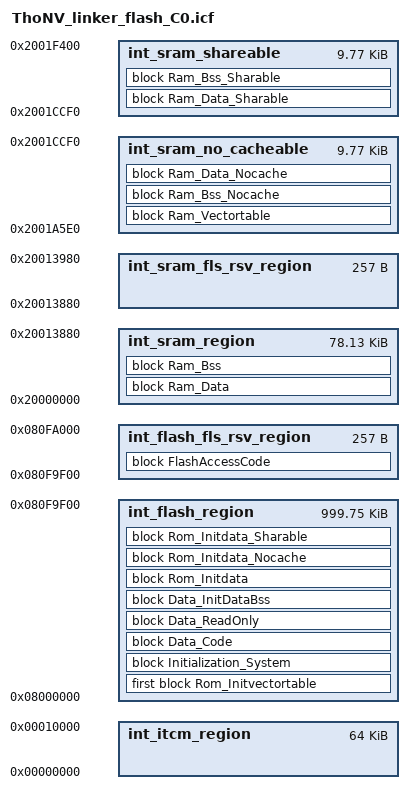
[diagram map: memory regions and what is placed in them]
define symbol region_ITCM_start                 = 0x00000000;
define symbol region_ITCM_end                   = 64K;    /* 64K */

define symbol region_DTCM_start                 = 0x10000000;
define symbol region_DTCM_end                   = 128K;    /* 128K */

define symbol region_FLASH_C0_start             = 0x08000000;
define symbol region_FLASH_C0_end               = 0x080F9F00; 

define symbol region_FLS_RSV_FLASH_C0_start     = 0x080F9F00;
define symbol region_FLS_RSV_FLASH_C0_end       = 0x080FA000; 

define symbol region_SRAM_C0_start              = 0x20000000;
define symbol region_SRAM_C0_end                = 0x20013880; 

define symbol region_FLS_RSV_RAM_C0_start       = 0x20013880;
define symbol region_FLS_RSV_RAM_C0_end         = 0x20013980; 

define symbol region_SRAM_STACK_C0_start       = 0x20013980;
define symbol region_SRAM_STACK_C0_end         = 0x2001A5E0; 

define symbol region_SRAM_NO_CACHEABLE_C0_start = 0x2001A5E0;
define symbol region_SRAM_NO_CACHEABLE_C0_end   = 0x2001CCF0;

define symbol region_SRAM_SHAREABLE_start       = 0x2001CCF0;
define symbol region_SRAM_SHAREABLE_end         = 0x2001F400; 

define symbol region_SRAM_END_C0                = 0x2001F400;

define exported symbol Stack_end_c0      = region_SRAM_STACK_C0_start;
define exported symbol Stack_start_c0    = region_SRAM_STACK_C0_end;


define exported symbol RAM_INIT          = 1;
define exported symbol INT_SRAM_START    = region_SRAM_C0_start;
define exported symbol INT_SRAM_END      = region_SRAM_END_C0;
define exported symbol ITCM_INIT         = 1;
define exported symbol INT_ITCM_START    = region_ITCM_start;
define exported symbol INT_ITCM_END      = region_ITCM_end;
define exported symbol DTCM_INIT         = 1;
define exported symbol INT_DTCM_START    = region_DTCM_start;
define exported symbol INT_DTCM_END      = region_DTCM_end;

/* Fls module access code support */
define exported symbol Fls_ACEraseRomStart  = region_FLS_RSV_FLASH_C0_start;
define exported symbol Fls_ACEraseRomEnd    = region_FLS_RSV_FLASH_C0_end ;
define exported symbol Fls_ACEraseSize      = (region_FLS_RSV_FLASH_C0_end - region_FLS_RSV_FLASH_C0_start)/4;

define exported symbol Fls_ACWriteRomStart  = region_FLS_RSV_FLASH_C0_start;
define exported symbol Fls_ACWriteRomEnd    = region_FLS_RSV_FLASH_C0_end ;
define exported symbol Fls_ACWriteSize      = (region_FLS_RSV_FLASH_C0_end - region_FLS_RSV_FLASH_C0_start)/4;

/* Fls module blank read support */
define exported symbol Fls_ACBlankReadRomStart  = region_FLS_RSV_FLASH_C0_start;
define exported symbol Fls_ACBlankReadRomEnd    = region_FLS_RSV_FLASH_C0_end ;
define exported symbol Fls_ACBlankReadSize      = (region_FLS_RSV_FLASH_C0_end - region_FLS_RSV_FLASH_C0_start) /4;

define exported symbol ERASE_FUNC_ADDRESS      = region_FLS_RSV_RAM_C0_start;
define exported symbol WRITE_FUNC_ADDRESS      = region_FLS_RSV_RAM_C0_start;
define exported symbol BLANK_READ_FUNC_ADDRESS = region_FLS_RSV_RAM_C0_start;

define memory mem with size = 4G;
define region int_flash_region         = mem:[from region_FLASH_C0_start to region_FLASH_C0_end];
define region int_flash_fls_rsv_region = mem:[from region_FLS_RSV_FLASH_C0_start to region_FLS_RSV_FLASH_C0_end];
define region int_sram_region          = mem:[from region_SRAM_C0_start to region_SRAM_C0_end];
define region int_sram_fls_rsv_region  = mem:[from region_FLS_RSV_RAM_C0_start to region_FLS_RSV_RAM_C0_end];
define region int_sram_no_cacheable    = mem:[from region_SRAM_NO_CACHEABLE_C0_start to region_SRAM_NO_CACHEABLE_C0_end];
define region int_sram_shareable       = mem:[from region_SRAM_SHAREABLE_start to region_SRAM_SHAREABLE_end];
define region int_itcm_region          = mem:[from region_ITCM_start to region_ITCM_end];
define region int_dtcm_region          = mem:[from region_DTCM_start to region_DTCM_end];

keep {symbol System_Sc_Config_Orig, symbol System_Sc_Config_Copy, symbol System_Sc_Config_OtpcrSts, symbol System_Sc_Config_PfuOtpcr};

define exported symbol VTABLE_INIT = start(int_flash_region);

initialize manually {
                     section .data,
                     section .mcal_data,
                     section .mcal_data_no_cacheable,
                     section .mcal_const_no_cacheable,
                     section .ramcode,
                     section .intvec
                    };

do not initialize { 
                    section .bss,
                    section .mcal_bss,
                    section .mcal_bss_no_cacheable,
                    section .mcal_shared_bss,
                    section .data,
                    section .mcal_data,
                    section .mcal_data_no_cacheable,
                    section .mcal_shared_data,
                    section .mcal_const_no_cacheable,
                    section .ramcode
                  };

/* Flash region */
define block Initialization_System with fixed order                 { section .startup, section .systeminit };
define block Data_Code with fixed order                             { section .text, section .mcal_text, section .acmcu_code_rom };
define block Data_ReadOnly with fixed order                         { section .rodata, section .mcal_const_cfg, section .mcal_const };
define block Data_InitDataBss with fixed order                      { section .init_table, section .zero_table, section .iar.* };
define block Rom_Initvectortable with fixed order, alignment = 4096 { section .intvec_init };
define block Rom_Initdata with fixed order, alignment = 4           { section .data_init, section .mcal_data_init, section .ramcode_init };
define block Rom_Initdata_Nocache with fixed order, alignment = 4   { section .mcal_data_no_cacheable_init, section .mcal_const_no_cacheable_init };
define block Rom_Initdata_Sharable with fixed order, alignment = 4  { section .mcal_shared_data_init };
define block FlashAccessCode with fixed order                       { section .acfls_code_rom};

/* Ram region */
define block Ram_Vectortable with fixed order, alignment = 4096     { section .intvec };
define block Ram_Data with fixed order, alignment = 4               { section .data, section .mcal_data, section .ramcode };
define block Ram_Data_Nocache with fixed order, alignment = 4       { section .mcal_data_no_cacheable, section .mcal_const_no_cacheable };
define block Ram_Data_Sharable with fixed order, alignment = 4      { section .mcal_shared_data };
define block Ram_Bss with fixed order, alignment = 4                { section .bss, section .mcal_bss };
define block Ram_Bss_Nocache with fixed order, alignment = 4        { section .mcal_bss_no_cacheable };
define block Ram_Bss_Sharable with fixed order, alignment = 4       { section .mcal_shared_bss };

place in int_flash_region         { first block Rom_Initvectortable };
place in int_flash_region         { block Initialization_System, block Data_Code, block Data_ReadOnly, block Data_InitDataBss };
place in int_flash_region         { block Rom_Initdata, block Rom_Initdata_Nocache, block Rom_Initdata_Sharable };
place in int_flash_fls_rsv_region { block FlashAccessCode };
place in int_sram_region          { block Ram_Data, block Ram_Bss };
place in int_sram_no_cacheable    { block Ram_Vectortable, block Ram_Bss_Nocache, block Ram_Data_Nocache };
place in int_sram_shareable       { block Ram_Data_Sharable, block Ram_Bss_Sharable };

define exported symbol ROM_CODE_START          = region_FLASH_C0_start;
define exported symbol RAM_SHAREABLE_START     = region_SRAM_SHAREABLE_start;
define exported symbol RAM_STACK_START         = region_SRAM_STACK_C0_start;
define exported symbol RAM_NO_CACHEABLE_START  = region_SRAM_NO_CACHEABLE_C0_start;
define exported symbol CORE_ID = 0;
